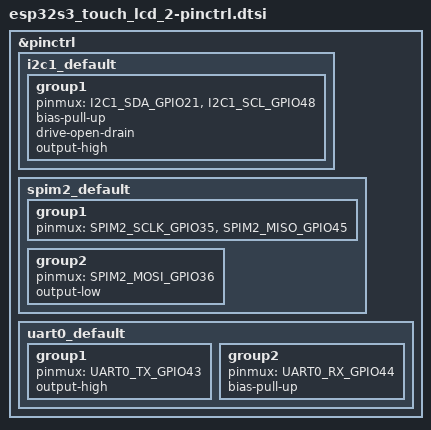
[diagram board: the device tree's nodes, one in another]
/*
 * Copyright (c) 2025, Frank Li<lgl88911@163.com>
 * SPDX-License-Identifier: Apache-2.0
 */

#include <dt-bindings/pinctrl/esp32s3-pinctrl.h>
#include <zephyr/dt-bindings/pinctrl/esp-pinctrl-common.h>
#include <zephyr/dt-bindings/pinctrl/esp32s3-gpio-sigmap.h>

&pinctrl {

	i2c1_default: i2c1_default {
		group1 {
			pinmux = <I2C1_SDA_GPIO21>, <I2C1_SCL_GPIO48>;
			bias-pull-up;
			drive-open-drain;
			output-high;
		};
	};

	spim2_default: spim2_default {
		group1 {
			pinmux = <SPIM2_SCLK_GPIO35>,<SPIM2_MISO_GPIO45>;
		};
		group2 {
			pinmux = <SPIM2_MOSI_GPIO36>;
			output-low;
		};
	};

	uart0_default: uart0_default {
		group1 {
			pinmux = <UART0_TX_GPIO43>;
			output-high;
		};
		group2 {
			pinmux = <UART0_RX_GPIO44>;
			bias-pull-up;
		};
	};
};
